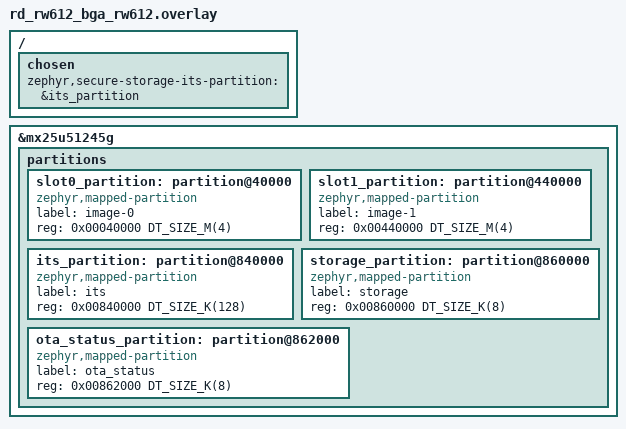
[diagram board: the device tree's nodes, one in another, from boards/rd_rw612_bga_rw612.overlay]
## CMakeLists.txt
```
# Copyright 2026 NXP
#
# SPDX-License-Identifier: Apache-2.0
#

cmake_minimum_required(VERSION 3.20.0)
find_package(Zephyr REQUIRED HINTS $ENV{ZEPHYR_BASE})
project(native_sim_component)

add_compile_definitions(ENABLE_TRACE)

set(CT_ROOT ${ZEPHYR_NXP_IOT_AGENT_MODULE_DIR}/tests/component)

target_sources(app PRIVATE
    ${CMAKE_CURRENT_SOURCE_DIR}/src/ztest_component_main.c
    ${ZEPHYR_NXP_IOT_AGENT_MODULE_DIR}/tests/common/canned_protobuf.c
    ${CT_ROOT}/common/mock_transport.c
    ${CT_ROOT}/common/wrap_ota_tls.c
    ${CT_ROOT}/internal_ota_lib/test_el2go_ota_lib_internal.c
    ${CT_ROOT}/public_ota_lib/test_el2go_ota_lib_public.c
)

# Redirect the real TLS functions to the stubs in wrap_ota_tls so that
# init/connect work on native_sim without a real TLS stack.
if(CONFIG_BOARD_NATIVE_SIM)
    zephyr_ld_options(
        -Wl,--wrap=el2go_ota_tls_init
        -Wl,--wrap=el2go_ota_tls_connect
        -Wl,--wrap=el2go_ota_tls_disconnect
        -Wl,--wrap=el2go_ota_tls_deinit
        -Wl,--wrap=el2go_ota_transport_init
    )
endif()

if(CONFIG_BOARD_NATIVE_SIM)
    target_sources(app PRIVATE
        ${CMAKE_CURRENT_SOURCE_DIR}/boards/native_sim/test_backend.c
        # No ELS PKC hardware on native_sim; shared with el2go_fwual_component.
        ${ZEPHYR_NXP_IOT_AGENT_MODULE_DIR}/zephyr/tests/common/platform_stubs.c
    )
else()
    target_sources(app PRIVATE ${CMAKE_CURRENT_SOURCE_DIR}/boards/rw612/test_backend.c)
endif()

zephyr_include_directories(
    ${ZEPHYR_NXP_IOT_AGENT_MODULE_DIR}/tests/common
    ${CT_ROOT}/framework
    ${CT_ROOT}/common
    ${CT_ROOT}/internal_ota_lib
    ${CT_ROOT}/public_ota_lib
    ${ZEPHYR_NXP_IOT_AGENT_MODULE_DIR}/include
    ${ZEPHYR_NXP_IOT_AGENT_MODULE_DIR}/priv
    ${ZEPHYR_NXP_IOT_AGENT_MODULE_DIR}/libs/protobuf/nanopb
    ${ZEPHYR_NXP_IOT_AGENT_MODULE_DIR}/libs/protobuf/ota
    ${ZEPHYR_NXP_IOT_AGENT_MODULE_DIR}/libs/el2go_ota_lib/src
    ${ZEPHYR_NXP_IOT_AGENT_MODULE_DIR}/libs/el2go_ota_lib/src/download
    ${ZEPHYR_NXP_IOT_AGENT_MODULE_DIR}/libs/el2go_ota_lib/src/transport
    ${ZEPHYR_NXP_IOT_AGENT_MODULE_DIR}/libs/net_crypto
    ${ZEPHYR_NXP_IOT_AGENT_MODULE_DIR}/libs/platforms
    ${ZEPHYR_NXP_IOT_AGENT_MODULE_DIR}/libs/osal/include
)

if(CONFIG_BOARD_NATIVE_SIM)
    zephyr_include_directories(
        ${ZEPHYR_MCUBOOT_MODULE_DIR}/boot/bootutil/include
        ${ZEPHYR_MCUBOOT_MODULE_DIR}/boot/zephyr/include
    )
endif()
```

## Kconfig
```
# Copyright 2026 NXP
# SPDX-License-Identifier: Apache-2.0

# The component test compiles libs/fwual/mcuboot/fwual_mcuboot.c directly on
# native_sim (with local stubs), so it needs CONFIG_FWUAL_MCUBOOT_IMAGE_COUNT
# visible regardless of whether BOOTLOADER_MCUBOOT is enabled (the module-level
# zephyr/Kconfig only sources this fragment under BOOTLOADER_MCUBOOT=y).
source "$(ZEPHYR_NXP_IOT_AGENT_MODULE_DIR)/libs/fwual/mcuboot/Kconfig"

source "Kconfig.zephyr"
```

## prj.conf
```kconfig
# Copyright 2026 NXP
# SPDX-License-Identifier: Apache-2.0

CONFIG_EL2GO_OTA_LIBRARY_SOURCES=y
CONFIG_EL2GO_OTA_PLATFORM_SOURCES=y
CONFIG_EL2GO_OTA_TESTS=y
CONFIG_PRINTK=y
CONFIG_ZTEST=y

CONFIG_EL2GO_OTA_CHUNK_SIZE=4

CONFIG_COMPILER_WARNINGS_AS_ERRORS=n

# PSA Crypto - mbedTLS software (no hardware ELS PKC driver on native_sim)
CONFIG_PSA_CRYPTO=y
CONFIG_MBEDTLS=y
CONFIG_MBEDTLS_BUILTIN=y
CONFIG_MBEDTLS_PSA_CRYPTO_C=y
CONFIG_MBEDTLS_ENABLE_HEAP=y
CONFIG_MBEDTLS_HEAP_SIZE=65536
CONFIG_MBEDTLS_SSL_PROTO_TLS1_2=y
CONFIG_MBEDTLS_SSL_IN_CONTENT_LEN=16384
CONFIG_MBEDTLS_SSL_OUT_CONTENT_LEN=16384
CONFIG_MBEDTLS_SSL_ALPN=y
CONFIG_MBEDTLS_X509_CRT_WRITE_C=y
CONFIG_MBEDTLS_X509_CSR_WRITE_C=y
CONFIG_MBEDTLS_PK_WRITE_C=y
CONFIG_MBEDTLS_X509_CRT_PARSE_C=y
CONFIG_MBEDTLS_ASN1_PARSE_C=y
CONFIG_MBEDTLS_SSL_SERVER_NAME_INDICATION=y
CONFIG_MBEDTLS_KEY_EXCHANGE_ECDHE_ECDSA_ENABLED=y

CONFIG_PSA_CRYPTO_ENABLE_ALL=y
CONFIG_PSA_WANT_ALG_ECDSA=y
CONFIG_PSA_WANT_ALG_ECDH=y
CONFIG_PSA_WANT_ALG_SHA_256=y
CONFIG_PSA_WANT_ALG_SHA_384=y
CONFIG_PSA_WANT_ALG_GCM=y
CONFIG_PSA_WANT_ECC_SECP_R1_256=y
CONFIG_PSA_WANT_KEY_TYPE_AES=y

CONFIG_SECURE_STORAGE=y
CONFIG_ZMS=y
CONFIG_SECURE_STORAGE_ITS_STORE_IMPLEMENTATION_ZMS=y


# flash
CONFIG_FLASH=y
CONFIG_FLASH_MAP=y
CONFIG_FLASH_PAGE_LAYOUT=y
CONFIG_NVS=y
CONFIG_FLASH_PAGE_LAYOUT=y
# Networking stack (required for net_crypto/mbedTLS TLS layer)
CONFIG_NETWORKING=y
CONFIG_NET_IPV4=y
CONFIG_NET_TCP=y
CONFIG_NET_SOCKETS=y

# General
CONFIG_REQUIRES_FULL_LIBC=y
CONFIG_POSIX_API=y
CONFIG_HEAP_MEM_POOL_SIZE=131072
CONFIG_MAIN_STACK_SIZE=16384
CONFIG_ZTEST_STACK_SIZE=16384
CONFIG_HWINFO=y
```

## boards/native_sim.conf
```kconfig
# Copyright 2026 NXP
# SPDX-License-Identifier: Apache-2.0

# native_sim-specific overrides for the el2go_ota component test.

CONFIG_EL2GO_OTA_PLATFORM_SOURCES=n

# Flash simulator (native_sim only)
CONFIG_FLASH_SIMULATOR=y
CONFIG_NVS=y
CONFIG_MPU_ALLOW_FLASH_WRITE=y
```

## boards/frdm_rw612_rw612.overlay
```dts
/*
 * Copyright 2026 NXP
 *
 * SPDX-License-Identifier: Apache-2.0
 */

/ {
    chosen {
        zephyr,secure-storage-its-partition = &its_partition;
    };
};

&w25q512jvfiq {
    partitions {
        /delete-node/ partition@760000;

        its_partition: partition@840000 {
            compatible = "zephyr,mapped-partition";
            label = "its";
            reg = <0x00840000 DT_SIZE_K(128)>;
        };

        storage_partition: partition@860000 {
            compatible = "zephyr,mapped-partition";
            label = "storage";
            reg = <0x00860000 DT_SIZE_K(8)>;
        };

        ota_status_partition: partition@862000 {
            compatible = "zephyr,mapped-partition";
            label = "ota_status";
            reg = <0x00862000 DT_SIZE_K(8)>;
        };
    };
};
```

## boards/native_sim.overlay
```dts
/*
 * Copyright 2026 NXP
 *
 * SPDX-License-Identifier: Apache-2.0
 */

/ {
    chosen {
        zephyr,secure-storage-its-partition = &its_partition;
    };
};

&flash0 {
    erase-block-size = <4096>;
    partitions {
        compatible = "fixed-partitions";
        #address-cells = <1>;
        #size-cells = <1>;

        its_partition: partition@120000 {
            compatible = "zephyr,mapped-partition";
            label = "its";
            reg = <0x00120000 DT_SIZE_K(128)>;
        };

        ota_status_partition: partition@140000 {
            compatible = "zephyr,mapped-partition";
            label = "ota_status";
            reg = <0x00140000 DT_SIZE_K(16)>;
        };
    };
};
```

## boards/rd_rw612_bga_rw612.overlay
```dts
/*
 * Copyright 2026 NXP
 *
 * SPDX-License-Identifier: Apache-2.0
 */

/ {
    chosen {
        zephyr,secure-storage-its-partition = &its_partition;
    };
};

&mx25u51245g {
    partitions {
        /delete-node/ partition@20000;
        /delete-node/ partition@c0000;
        /delete-node/ partition@3c0000;
        /delete-node/ partition@460000;
        /delete-node/ partition@760000;

        slot0_partition: partition@40000 {
            compatible = "zephyr,mapped-partition";
            label = "image-0";
            reg = <0x00040000 DT_SIZE_M(4)>;
        };

        slot1_partition: partition@440000 {
            compatible = "zephyr,mapped-partition";
            label = "image-1";
            reg = <0x00440000 DT_SIZE_M(4)>;
        };

        its_partition: partition@840000 {
            compatible = "zephyr,mapped-partition";
            label = "its";
            reg = <0x00840000 DT_SIZE_K(128)>;
        };

        storage_partition: partition@860000 {
            compatible = "zephyr,mapped-partition";
            label = "storage";
            reg = <0x00860000 DT_SIZE_K(8)>;
        };

        ota_status_partition: partition@862000 {
            compatible = "zephyr,mapped-partition";
            label = "ota_status";
            reg = <0x00862000 DT_SIZE_K(8)>;
        };
    };
};
```

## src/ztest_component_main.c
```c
/*
 * Copyright 2026 NXP
 *
 * SPDX-License-Identifier: Apache-2.0
 *
 */

#include <zephyr/ztest.h>

#include "test_ztest.h"

#include "test_el2go_ota_lib_internal.h"
#include "test_el2go_ota_lib_public.h"

ZTEST_SUITE(el2go_ct, NULL, NULL, NULL, NULL, NULL);

TEST_ZTEST_SUITE(el2go_ct, ota_lib_internal)
TEST_ZTEST_SUITE(el2go_ct, ota_lib_public)
```
